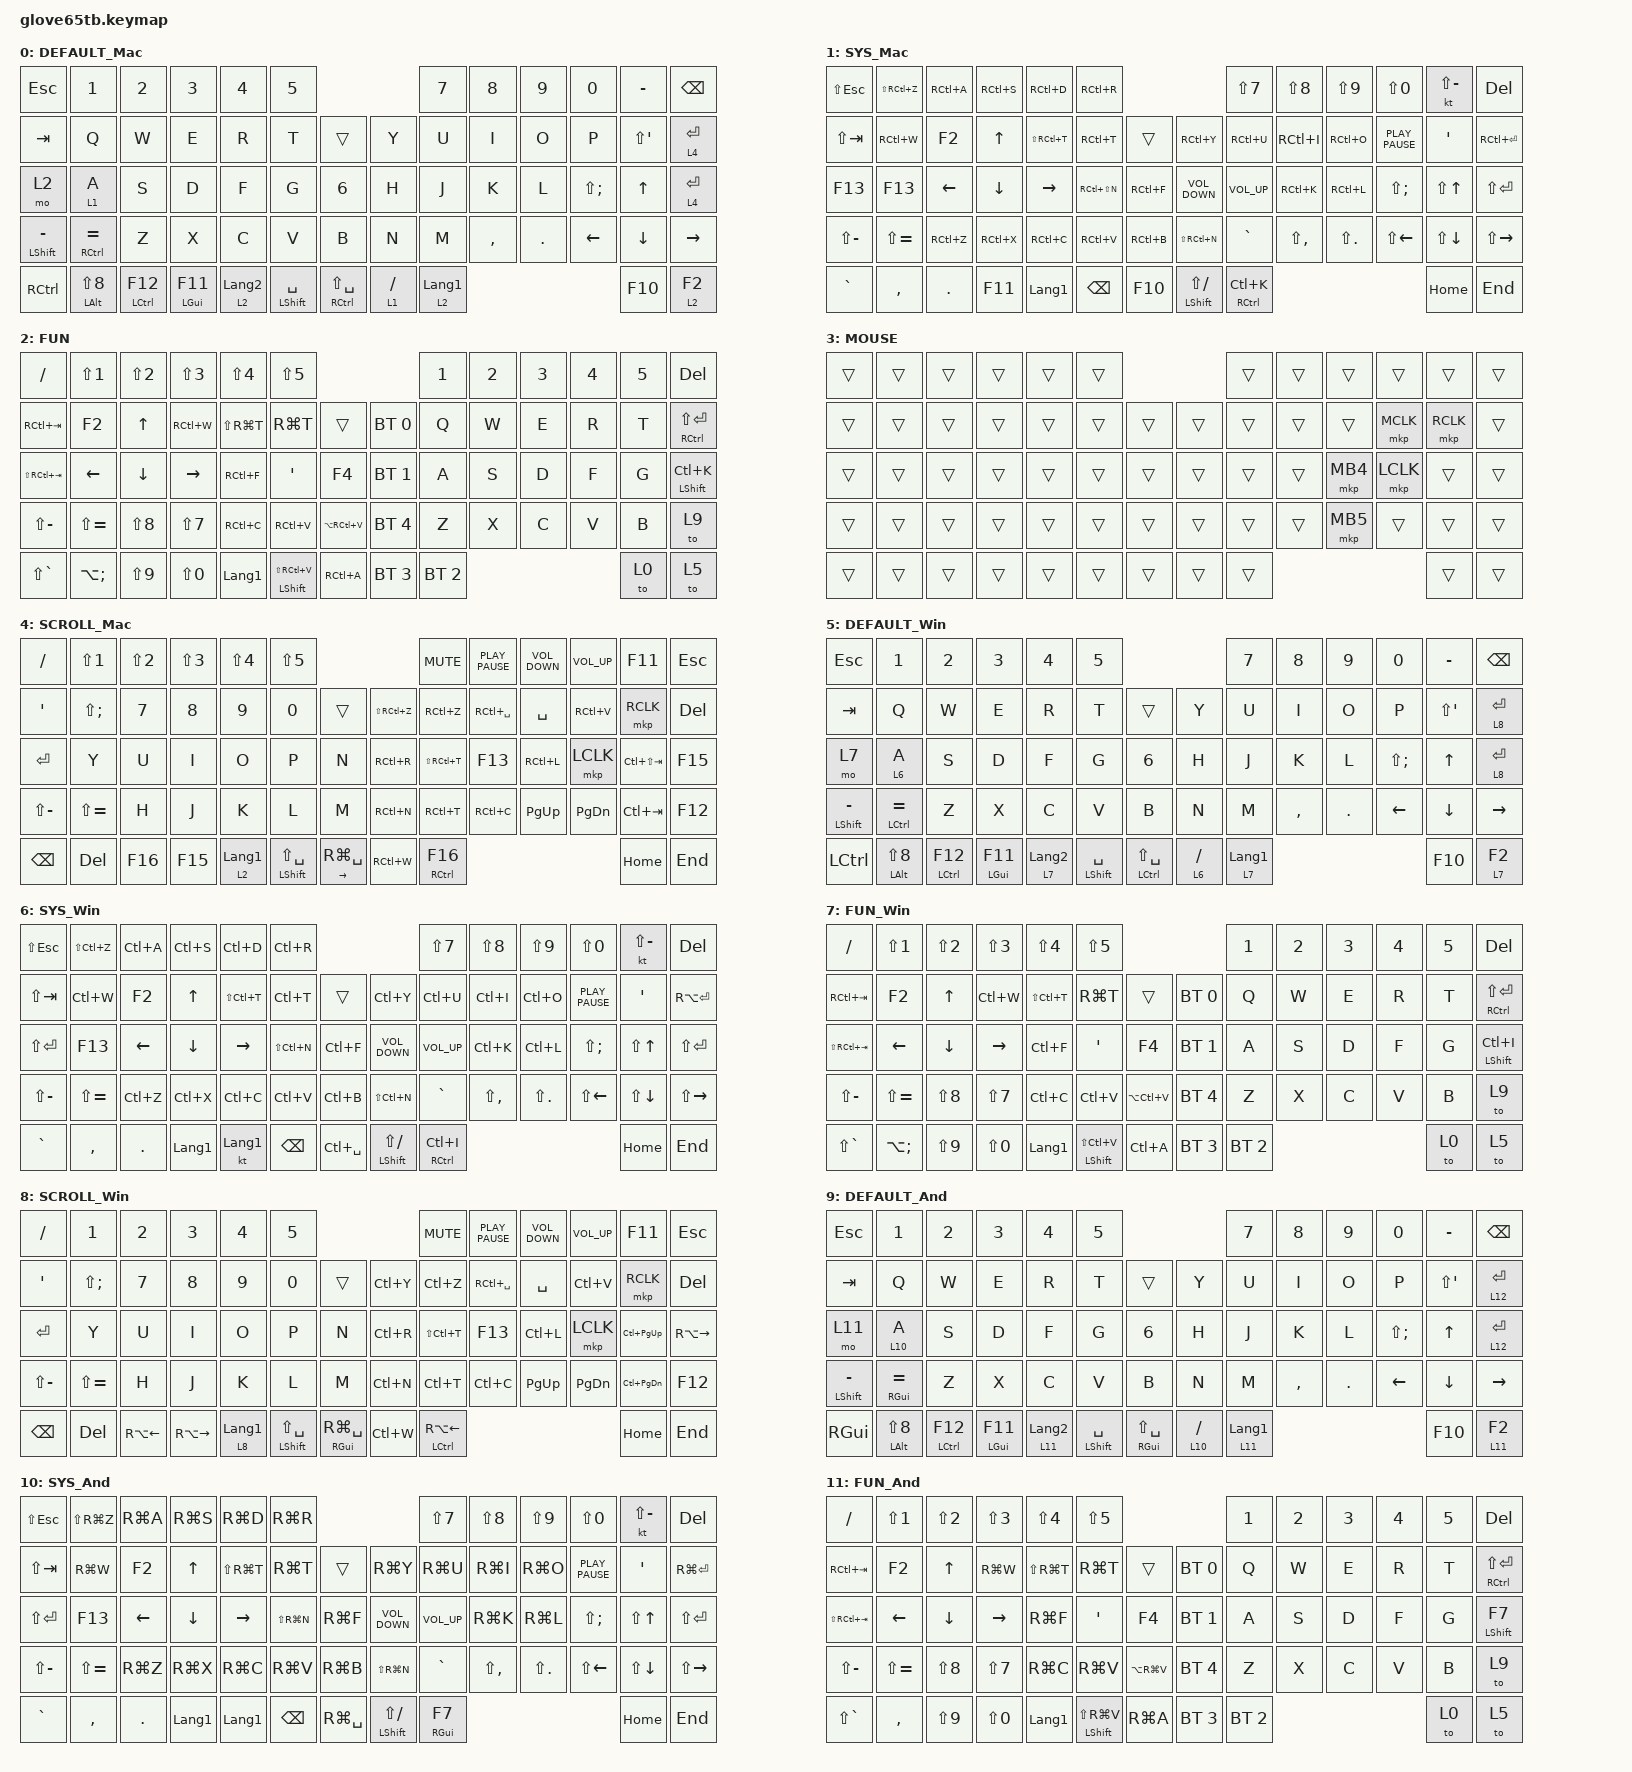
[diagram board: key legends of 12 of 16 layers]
#define ZMK_POINTING_DEFAULT_SCRL_VAL 150

#include <behaviors/rgbled_widget.dtsi>
#include <dt-bindings/zmk/input_transform.h>
#include <input/processors.dtsi>
#include <zephyr/dt-bindings/input/input-event-codes.h>
#include <behaviors.dtsi>
#include <dt-bindings/zmk/bt.h>
#include <dt-bindings/zmk/keys.h>
#include <dt-bindings/zmk/pointing.h>

// Layer Numbering

#define DEFAULT 0
#define NUM     1
#define SYM     2
#define FUN     3
#define MOUSE   4
#define SCROLL  5

&mmv {
    delay-ms = <20>;
    trigger-period-ms = <5>;
    time-to-max-speed-ms = <100>;
    acceleration-exponent = <2>;
};

&msc {
    delay-ms = <3>;
    trigger-period-ms = <3>;
    time-to-max-speed-ms = <100>;
    acceleration-exponent = <0>;
};

/ {
    input_processors {
        zip_wheel_scaler: zip_wheel_scaler {
            compatible = "zmk,input-processor-scaler";
            #input-processor-cells = <2>;
            type = <INPUT_EV_REL>;
            codes = <INPUT_REL_WHEEL>;
            track-remainders;
        };
    };
};

/ {
    combos { compatible = "zmk,combos"; };

    behaviors {
        sensor_rotate_kp: sensor_rotate_kp {
            compatible = "zmk,behavior-sensor-rotate-var";
            #sensor-binding-cells = <2>;
            bindings = <&kp>, <&kp>;
        };

        mouse_wheel_scroll: mouse_wheel_scroll {
            compatible = "zmk,behavior-sensor-rotate-var";
            #sensor-binding-cells = <2>;
            bindings = <&msc>, <&msc>;

            tap-ms = <20>;
        };
    };

    macros {
        new_win: new_win {
            compatible = "zmk,behavior-macro";
            #binding-cells = <0>;
            bindings = <&bt BT_SEL 2>, <&macro_wait_time 200>, <&to 5>;

            label = "NEW_WIN";
        };

        new_android: new_android {
            compatible = "zmk,behavior-macro";
            #binding-cells = <0>;
            bindings = <&bt BT_SEL 1>, <&macro_wait_time 200>, <&to 9>;

            label = "NEW_ANDROID";
        };

        new_mac: new_macro {
            compatible = "zmk,behavior-macro";
            #binding-cells = <0>;
            bindings = <&bt BT_SEL 3>, <&macro_wait_time 200>, <&to 0>;

            label = "NEW_MACRO";
        };

        new_iPad: new_iPad {
            compatible = "zmk,behavior-macro";
            #binding-cells = <0>;
            bindings = <&bt BT_SEL 4>, <&macro_wait_time 200>, <&to 9>;

            label = "NEW_IPAD";
        };
    };

    keymap {
        compatible = "zmk,keymap";

        DEFAULT_Mac {
            label = "DEFAULT_Mac";
            bindings = <
&kp ESC               &kp N1                   &kp N2                &kp N3            &kp N4            &kp N5                                                         &kp N7            &kp N8     &kp N9      &kp N0          &kp MINUS       &kp BSPC
&kp TAB               &kp Q                    &kp W                 &kp E             &kp R             &kp T                 &trans                       &kp Y       &kp U             &kp I      &kp O       &kp P           &kp LS(APOS)    &lt 4 RET
&mo 2                 &lt 1 A                  &kp S                 &kp D             &kp F             &kp G                 &kp N6                       &kp H       &kp J             &kp K      &kp L       &kp LS(SEMI)    &kp UP_ARROW    &lt 4 RET
&mt LEFT_SHIFT MINUS  &mt RIGHT_CONTROL EQUAL  &kp Z                 &kp X             &kp C             &kp V                 &kp B                        &kp N       &kp M             &kp COMMA  &kp PERIOD  &kp LEFT_ARROW  &kp DOWN_ARROW  &kp RIGHT_ARROW
&kp RIGHT_CONTROL     &mt LEFT_ALT LS(N8)      &mt LEFT_CONTROL F12  &mt LEFT_GUI F11  &lt 2 LANGUAGE_2  &mt LEFT_SHIFT SPACE  &mt RIGHT_CONTROL LS(SPACE)  &lt 1 FSLH  &lt 2 LANGUAGE_1                                         &kp F10         &lt 2 F2
            >;

            sensor-bindings = <&mouse_wheel_scroll SCRL_UP SCRL_DOWN>;
        };

        SYS_Mac {
            label = "SYS_Mac";
            bindings = <
&kp LS(ESCAPE)  &kp LS(RC(Z))  &kp RC(A)       &kp RC(S)       &kp RC(D)       &kp RC(R)                                          &kp LS(N7)               &kp LS(N8)     &kp LS(N9)      &kp LS(N0)          &kt LS(MINUS)       &kp DEL
&kp LS(TAB)     &kp RC(W)      &kp F2          &kp UP_ARROW    &kp LS(RC(T))   &kp RC(T)      &trans     &kp RC(Y)                &kp RC(U)                &kp RC(I)      &kp RC(O)       &kp K_PLAY_PAUSE    &kp APOS            &kp RC(RET)
&kp F13         &kp F13        &kp LEFT_ARROW  &kp DOWN_ARROW  &kp RIGHT       &kp RC(LS(N))  &kp RC(F)  &kp C_VOLUME_DOWN        &kp C_VOLUME_UP          &kp RC(K)      &kp RC(L)       &kp LS(SEMI)        &kp LS(UP_ARROW)    &kp LS(RET)
&kp LS(MINUS)   &kp LS(EQUAL)  &kp RC(Z)       &kp RC(X)       &kp RC(C)       &kp RC(V)      &kp RC(B)  &kp LS(RC(N))            &kp GRAVE                &kp LS(COMMA)  &kp LS(PERIOD)  &kp LS(LEFT_ARROW)  &kp LS(DOWN_ARROW)  &kp LS(RIGHT_ARROW)
&kp GRAVE       &kp COMMA      &kp PERIOD      &kp F11         &kp LANGUAGE_1  &kp BACKSPACE  &kp F10    &mt LEFT_SHIFT LS(FSLH)  &mt RIGHT_CONTROL LC(K)                                                     &kp HOME            &kp END
            >;

            sensor-bindings = <&mouse_wheel_scroll SCRL_LEFT SCRL_RIGHT>;
        };

        function_Mac {
            label = "FUN";
            bindings = <
&kp FSLH         &kp LS(NUMBER_1)   &kp LS(NUMBER_2)  &kp LS(NUMBER_3)  &kp LS(NUMBER_4)  &kp LS(N5)                                             &kp NUMBER_1  &kp NUMBER_2  &kp NUMBER_3  &kp NUMBER_4  &kp N5  &kp DELETE
&kp RC(TAB)      &kp F2             &kp UP_ARROW      &kp RC(W)         &kp LS(RG(T))     &kp RG(T)                 &trans         &bt BT_SEL 0  &kp Q         &kp W         &kp E         &kp R         &kp T   &mt RIGHT_CONTROL LS(RET)
&kp LS(RC(TAB))  &kp LEFT           &kp DOWN          &kp RIGHT         &kp RC(F)         &kp APOS                  &kp F4         &bt BT_SEL 1  &kp A         &kp S         &kp D         &kp F         &kp G   &mt LEFT_SHIFT LC(K)
&kp LS(MINUS)    &kp LS(EQUAL)      &kp LS(N8)        &kp LS(N7)        &kp RC(C)         &kp RC(V)                 &kp LA(RC(V))  &bt BT_SEL 4  &kp Z         &kp X         &kp C         &kp V         &kp B   &to 9
&kp LS(GRAVE)    &kp LA(SEMICOLON)  &kp LS(N9)        &kp LS(N0)        &kp LANGUAGE_1    &mt LEFT_SHIFT LS(RC(V))  &kp RC(A)      &bt BT_SEL 3  &bt BT_SEL 2                                            &to 0   &to 5
            >;

            sensor-bindings = <&sensor_rotate_kp C_VOLUME_DOWN C_VOLUME_UP>;
        };

        mouse_layer {
            label = "MOUSE";
            bindings = <
&trans  &trans  &trans  &trans  &trans  &trans                  &trans  &trans  &trans    &trans     &trans     &trans
&trans  &trans  &trans  &trans  &trans  &trans  &trans  &trans  &trans  &trans  &trans    &mkp MCLK  &mkp RCLK  &trans
&trans  &trans  &trans  &trans  &trans  &trans  &trans  &trans  &trans  &trans  &mkp MB4  &mkp LCLK  &trans     &trans
&trans  &trans  &trans  &trans  &trans  &trans  &trans  &trans  &trans  &trans  &mkp MB5  &trans     &trans     &trans
&trans  &trans  &trans  &trans  &trans  &trans  &trans  &trans  &trans                               &trans     &trans
            >;
        };

        SCROLL_Mac {
            label = "SCROLL_Mac";
            bindings = <
&kp FSLH       &kp LS(NUMBER_1)  &kp LS(NUMBER_2)  &kp LS(NUMBER_3)  &kp LS(NUMBER_4)  &kp LS(N5)                                                          &kp K_MUTE             &kp K_PLAY_PAUSE  &kp C_VOLUME_DOWN  &kp C_VOLUME_UP  &kp F11          &kp ESCAPE
&kp APOS       &kp LS(SEMI)      &kp N7            &kp N8            &kp N9            &kp N0                    &trans                     &kp LS(RC(Z))  &kp RC(Z)              &kp RC(SPACE)     &kp SPACE          &kp RC(V)        &mkp RCLK        &kp DELETE
&kp RET        &kp Y             &kp U             &kp I             &kp O             &kp P                     &kp N                      &kp RC(R)      &kp LS(RC(T))          &kp F13           &kp RC(L)          &mkp LCLK        &kp LC(LS(TAB))  &kp F15
&kp LS(MINUS)  &kp LS(EQUAL)     &kp H             &kp J             &kp K             &kp L                     &kp M                      &kp RC(N)      &kp RC(T)              &kp RC(C)         &kp PAGE_UP        &kp PAGE_DOWN    &kp LC(TAB)      &kp F12
&kp BACKSPACE  &kp DELETE        &kp F16           &kp F15           &lt 2 LANGUAGE_1  &mt LEFT_SHIFT LS(SPACE)  &mt RIGHT_ARROW RG(SPACE)  &kp RC(W)      &mt RIGHT_CONTROL F16                                                        &kp HOME         &kp END
            >;

            sensor-bindings = <&inc_dec_kp C_VOLUME_DOWN C_VOLUME_UP>;
        };

        DEFAULT_Win {
            label = "DEFAULT_Win";
            bindings = <
&kp ESC               &kp N1                  &kp N2                &kp N3            &kp N4            &kp N5                                                        &kp N7            &kp N8     &kp N9      &kp N0          &kp MINUS       &kp BSPC
&kp TAB               &kp Q                   &kp W                 &kp E             &kp R             &kp T                 &trans                      &kp Y       &kp U             &kp I      &kp O       &kp P           &kp LS(APOS)    &lt 8 RET
&mo 7                 &lt 6 A                 &kp S                 &kp D             &kp F             &kp G                 &kp N6                      &kp H       &kp J             &kp K      &kp L       &kp LS(SEMI)    &kp UP_ARROW    &lt 8 RET
&mt LEFT_SHIFT MINUS  &mt LEFT_CONTROL EQUAL  &kp Z                 &kp X             &kp C             &kp V                 &kp B                       &kp N       &kp M             &kp COMMA  &kp PERIOD  &kp LEFT_ARROW  &kp DOWN_ARROW  &kp RIGHT_ARROW
&kp LEFT_CONTROL      &mt LEFT_ALT LS(N8)     &mt LEFT_CONTROL F12  &mt LEFT_GUI F11  &lt 7 LANGUAGE_2  &mt LEFT_SHIFT SPACE  &mt LEFT_CONTROL LS(SPACE)  &lt 6 FSLH  &lt 7 LANGUAGE_1                                         &kp F10         &lt 7 F2
            >;

            sensor-bindings = <&mouse_wheel_scroll SCRL_UP SCRL_DOWN>;
        };

        SYS_Win {
            label = "SYS_Win";
            bindings = <
&kp LS(ESCAPE)  &kp LS(LC(Z))  &kp LC(A)       &kp LC(S)       &kp LC(D)       &kp LC(R)                                              &kp LS(N7)               &kp LS(N8)     &kp LS(N9)      &kp LS(N0)          &kt LS(MINUS)       &kp DEL
&kp LS(TAB)     &kp LC(W)      &kp F2          &kp UP_ARROW    &kp LS(LC(T))   &kp LC(T)      &trans         &kp LC(Y)                &kp LC(U)                &kp LC(I)      &kp LC(O)       &kp K_PLAY_PAUSE    &kp APOS            &kp RA(RET)
&kp LS(RET)     &kp F13        &kp LEFT_ARROW  &kp DOWN_ARROW  &kp RIGHT       &kp LS(LC(N))  &kp LC(F)      &kp C_VOLUME_DOWN        &kp C_VOLUME_UP          &kp LC(K)      &kp LC(L)       &kp LS(SEMI)        &kp LS(UP_ARROW)    &kp LS(RET)
&kp LS(MINUS)   &kp LS(EQUAL)  &kp LC(Z)       &kp LC(X)       &kp LC(C)       &kp LC(V)      &kp LC(B)      &kp LS(LC(N))            &kp GRAVE                &kp LS(COMMA)  &kp LS(PERIOD)  &kp LS(LEFT_ARROW)  &kp LS(DOWN_ARROW)  &kp LS(RIGHT_ARROW)
&kp GRAVE       &kp COMMA      &kp PERIOD      &kp LANGUAGE_1  &kt LANGUAGE_1  &kp BACKSPACE  &kp LC(SPACE)  &mt LEFT_SHIFT LS(FSLH)  &mt RIGHT_CONTROL LC(I)                                                     &kp HOME            &kp END
            >;

            sensor-bindings = <&mouse_wheel_scroll SCRL_LEFT SCRL_RIGHT>;
        };

        function_Win {
            label = "FUN_Win";
            bindings = <
&kp FSLH         &kp LS(NUMBER_1)   &kp LS(NUMBER_2)  &kp LS(NUMBER_3)  &kp LS(NUMBER_4)  &kp LS(N5)                                             &kp NUMBER_1  &kp NUMBER_2  &kp NUMBER_3  &kp NUMBER_4  &kp N5  &kp DELETE
&kp RC(TAB)      &kp F2             &kp UP_ARROW      &kp LC(W)         &kp LS(LC(T))     &kp RG(T)                 &trans         &bt BT_SEL 0  &kp Q         &kp W         &kp E         &kp R         &kp T   &mt RIGHT_CONTROL LS(RET)
&kp LS(RC(TAB))  &kp LEFT           &kp DOWN          &kp RIGHT         &kp LC(F)         &kp APOS                  &kp F4         &bt BT_SEL 1  &kp A         &kp S         &kp D         &kp F         &kp G   &mt LEFT_SHIFT LC(I)
&kp LS(MINUS)    &kp LS(EQUAL)      &kp LS(N8)        &kp LS(N7)        &kp LC(C)         &kp LC(V)                 &kp LA(LC(V))  &bt BT_SEL 4  &kp Z         &kp X         &kp C         &kp V         &kp B   &to 9
&kp LS(GRAVE)    &kp LA(SEMICOLON)  &kp LS(N9)        &kp LS(N0)        &kp LANGUAGE_1    &mt LEFT_SHIFT LS(LC(V))  &kp LC(A)      &bt BT_SEL 3  &bt BT_SEL 2                                            &to 0   &to 5
            >;

            sensor-bindings = <&sensor_rotate_kp C_VOLUME_DOWN C_VOLUME_UP>;
        };

        SCROLL_Win {
            label = "SCROLL_Win";
            bindings = <
&kp FSLH       &kp NUMBER_1   &kp NUMBER_2        &kp NUMBER_3   &kp NUMBER_4      &kp N5                                                        &kp K_MUTE                 &kp K_PLAY_PAUSE  &kp C_VOLUME_DOWN  &kp C_VOLUME_UP  &kp F11            &kp ESCAPE
&kp APOS       &kp LS(SEMI)   &kp N7              &kp N8         &kp N9            &kp N0                    &trans                   &kp LC(Y)  &kp LC(Z)                  &kp RC(SPACE)     &kp SPACE          &kp LC(V)        &mkp RCLK          &kp DELETE
&kp RET        &kp Y          &kp U               &kp I          &kp O             &kp P                     &kp N                    &kp LC(R)  &kp LS(LC(T))              &kp F13           &kp LC(L)          &mkp LCLK        &kp LC(PAGE_UP)    &kp RA(RIGHT)
&kp LS(MINUS)  &kp LS(EQUAL)  &kp H               &kp J          &kp K             &kp L                     &kp M                    &kp LC(N)  &kp LC(T)                  &kp LC(C)         &kp PAGE_UP        &kp PAGE_DOWN    &kp LC(PAGE_DOWN)  &kp F12
&kp BACKSPACE  &kp DELETE     &kp RA(LEFT_ARROW)  &kp RA(RIGHT)  &lt 8 LANGUAGE_1  &mt LEFT_SHIFT LS(SPACE)  &mt RIGHT_GUI RG(SPACE)  &kp LC(W)  &mt LEFT_CONTROL RA(LEFT)                                                        &kp HOME           &kp END
            >;

            sensor-bindings = <&inc_dec_kp C_VOLUME_DOWN C_VOLUME_UP>;
        };

        DEFAULT_And {
            label = "DEFAULT_And";
            bindings = <
&kp ESC               &kp N1               &kp N2                &kp N3            &kp N4             &kp N5                                                      &kp N7             &kp N8     &kp N9      &kp N0          &kp MINUS       &kp BSPC
&kp TAB               &kp Q                &kp W                 &kp E             &kp R              &kp T                 &trans                   &kp Y        &kp U              &kp I      &kp O       &kp P           &kp LS(APOS)    &lt 12 RET
&mo 11                &lt 10 A             &kp S                 &kp D             &kp F              &kp G                 &kp N6                   &kp H        &kp J              &kp K      &kp L       &kp LS(SEMI)    &kp UP_ARROW    &lt 12 RET
&mt LEFT_SHIFT MINUS  &mt RIGHT_GUI EQUAL  &kp Z                 &kp X             &kp C              &kp V                 &kp B                    &kp N        &kp M              &kp COMMA  &kp PERIOD  &kp LEFT_ARROW  &kp DOWN_ARROW  &kp RIGHT_ARROW
&kp RIGHT_GUI         &mt LEFT_ALT LS(N8)  &mt LEFT_CONTROL F12  &mt LEFT_GUI F11  &lt 11 LANGUAGE_2  &mt LEFT_SHIFT SPACE  &mt RIGHT_GUI LS(SPACE)  &lt 10 FSLH  &lt 11 LANGUAGE_1                                         &kp F10         &lt 11 F2
            >;

            sensor-bindings = <&mouse_wheel_scroll SCRL_UP SCRL_DOWN>;
        };

        SYS_And {
            label = "SYS_And";
            bindings = <
&kp LS(ESCAPE)  &kp LS(RG(Z))  &kp RG(A)       &kp RG(S)       &kp RG(D)       &kp RG(R)                                              &kp LS(N7)        &kp LS(N8)     &kp LS(N9)      &kp LS(N0)          &kt LS(MINUS)       &kp DEL
&kp LS(TAB)     &kp RG(W)      &kp F2          &kp UP_ARROW    &kp LS(RG(T))   &kp RG(T)      &trans         &kp RG(Y)                &kp RG(U)         &kp RG(I)      &kp RG(O)       &kp K_PLAY_PAUSE    &kp APOS            &kp RG(RET)
&kp LS(RET)     &kp F13        &kp LEFT_ARROW  &kp DOWN_ARROW  &kp RIGHT       &kp LS(RG(N))  &kp RG(F)      &kp C_VOLUME_DOWN        &kp C_VOLUME_UP   &kp RG(K)      &kp RG(L)       &kp LS(SEMI)        &kp LS(UP_ARROW)    &kp LS(RET)
&kp LS(MINUS)   &kp LS(EQUAL)  &kp RG(Z)       &kp RG(X)       &kp RG(C)       &kp RG(V)      &kp RG(B)      &kp LS(RG(N))            &kp GRAVE         &kp LS(COMMA)  &kp LS(PERIOD)  &kp LS(LEFT_ARROW)  &kp LS(DOWN_ARROW)  &kp LS(RIGHT_ARROW)
&kp GRAVE       &kp COMMA      &kp PERIOD      &kp LANGUAGE_1  &kp LANGUAGE_1  &kp BACKSPACE  &kp RG(SPACE)  &mt LEFT_SHIFT LS(FSLH)  &mt RIGHT_GUI F7                                                     &kp HOME            &kp END
            >;

            sensor-bindings = <&mouse_wheel_scroll SCRL_LEFT SCRL_RIGHT>;
        };

        function_And {
            label = "FUN_And";
            bindings = <
&kp FSLH         &kp LS(NUMBER_1)  &kp LS(NUMBER_2)  &kp LS(NUMBER_3)  &kp LS(NUMBER_4)  &kp LS(N5)                                             &kp NUMBER_1  &kp NUMBER_2  &kp NUMBER_3  &kp NUMBER_4  &kp N5  &kp DELETE
&kp RC(TAB)      &kp F2            &kp UP_ARROW      &kp RG(W)         &kp LS(RG(T))     &kp RG(T)                 &trans         &bt BT_SEL 0  &kp Q         &kp W         &kp E         &kp R         &kp T   &mt RIGHT_CONTROL LS(RET)
&kp LS(RC(TAB))  &kp LEFT          &kp DOWN          &kp RIGHT         &kp RG(F)         &kp APOS                  &kp F4         &bt BT_SEL 1  &kp A         &kp S         &kp D         &kp F         &kp G   &mt LEFT_SHIFT F7
&kp LS(MINUS)    &kp LS(EQUAL)     &kp LS(N8)        &kp LS(N7)        &kp RG(C)         &kp RG(V)                 &kp LA(RG(V))  &bt BT_SEL 4  &kp Z         &kp X         &kp C         &kp V         &kp B   &to 9
&kp LS(GRAVE)    &kp COMMA         &kp LS(N9)        &kp LS(N0)        &kp LANGUAGE_1    &mt LEFT_SHIFT LS(RG(V))  &kp RG(A)      &bt BT_SEL 3  &bt BT_SEL 2                                            &to 0   &to 5
            >;

            sensor-bindings = <&sensor_rotate_kp C_VOLUME_DOWN C_VOLUME_UP>;
        };

        SCROLL_And {
            label = "SCROLL_And";
            bindings = <
&kp FSLH       &kp NUMBER_1   &kp NUMBER_2  &kp NUMBER_3   &kp NUMBER_4      &kp N5                                                            &kp K_MUTE                  &kp K_PLAY_PAUSE  &kp C_VOLUME_DOWN  &kp C_VOLUME_UP  &kp LC(UP_ARROW)  &kp ESCAPE
&kp APOS       &kp LS(SEMI)   &kp N7        &kp N8         &kp N9            &kp N0                    &trans                   &kp LS(RC(Z))  &kp RC(Z)                   &kp RC(SPACE)     &kp SPACE          &kp RC(V)        &mkp RCLK         &kp DELETE
&kp RET        &kp Y          &kp U         &kp I          &kp O             &kp P                     &kp N                    &kp RC(R)      &kp LS(RC(T))               &kp F13           &kp RC(L)          &mkp LCLK        &kp RG(LS(TAB))   &kp RA(RIGHT)
&kp LS(MINUS)  &kp LS(EQUAL)  &kp H         &kp J          &kp K             &kp L                     &kp M                    &kp RC(N)      &kp RC(T)                   &kp RC(C)         &kp PAGE_UP        &kp PAGE_DOWN    &kp RG(TAB)       &kp LC(DOWN_ARROW)
&kp BACKSPACE  &kp DELETE     &kp RA(LEFT)  &kp RA(RIGHT)  &lt 2 LANGUAGE_1  &mt LEFT_SHIFT LS(SPACE)  &mt RIGHT_GUI RG(SPACE)  &kp RC(W)      &mt RIGHT_CONTROL RA(LEFT)                                                        &kp HOME          &kp END
            >;

            sensor-bindings = <&inc_dec_kp C_VOLUME_DOWN C_VOLUME_UP>;
        };

        layer_13 {
            bindings = <
&trans  &trans  &trans  &trans  &trans  &trans                  &trans  &trans  &trans  &trans  &trans  &trans
&trans  &trans  &trans  &trans  &trans  &trans  &trans  &trans  &trans  &trans  &trans  &trans  &trans  &kp RET
&trans  &trans  &trans  &trans  &trans  &trans  &trans  &trans  &trans  &trans  &trans  &trans  &trans  &kp RET
&trans  &trans  &trans  &trans  &trans  &trans  &trans  &trans  &trans  &trans  &trans  &trans  &trans  &trans
&trans  &trans  &trans  &trans  &trans  &trans  &trans  &trans  &trans                          &trans  &trans
            >;
        };

        layer_14 {
            bindings = <
&trans  &trans  &trans  &trans  &trans  &trans                  &trans  &trans  &trans  &trans  &trans  &trans
&trans  &trans  &trans  &trans  &trans  &trans  &trans  &trans  &trans  &trans  &trans  &trans  &trans  &trans
&trans  &trans  &trans  &trans  &trans  &trans  &trans  &trans  &trans  &trans  &trans  &trans  &trans  &trans
&trans  &trans  &trans  &trans  &trans  &trans  &trans  &trans  &trans  &trans  &trans  &trans  &trans  &trans
&trans  &trans  &trans  &trans  &trans  &trans  &trans  &trans  &trans                          &trans  &trans
            >;
        };

        layer_15 {
            bindings = <
&trans  &trans  &trans  &trans  &trans  &trans                  &trans  &trans  &trans  &trans  &trans  &trans
&trans  &trans  &trans  &trans  &trans  &trans  &trans  &trans  &trans  &trans  &trans  &trans  &trans  &trans
&trans  &trans  &trans  &trans  &trans  &trans  &trans  &trans  &trans  &trans  &trans  &trans  &trans  &trans
&trans  &trans  &trans  &trans  &trans  &trans  &trans  &trans  &trans  &trans  &trans  &trans  &trans  &trans
&trans  &trans  &trans  &trans  &trans  &trans  &trans  &trans  &trans                          &trans  &trans
            >;
        };
    };
};
